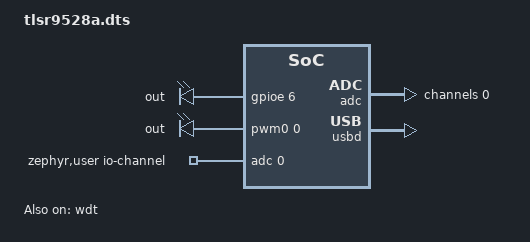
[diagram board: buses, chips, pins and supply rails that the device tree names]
/*
 * Copyright (c) 2023-2024 Telink Semiconductor
 *
 * SPDX-License-Identifier: Apache-2.0
 */

/dts-v1/;

#include "tlsr9528a-common.dtsi"

/ {
	led_pool {
		compatible = "gpio-leds";

		out {
			gpios = <&gpioe 6 GPIO_ACTIVE_HIGH>;
		};
	};

	pwm_pool {
		compatible = "pwm-leds";
		out {
			pwms =  <&pwm0 0 PWM_MSEC(1) PWM_POLARITY_NORMAL>,
					<&pwm0 1 PWM_MSEC(1) PWM_POLARITY_NORMAL>,
					<&pwm0 2 PWM_MSEC(1) PWM_POLARITY_NORMAL>,
					<&pwm0 3 PWM_MSEC(1) PWM_POLARITY_NORMAL>,
					<&pwm0 4 PWM_MSEC(1) PWM_POLARITY_NORMAL>,
					<&pwm0 5 PWM_MSEC(1) PWM_POLARITY_NORMAL>;
		};
	};

	zephyr,user {
		/* adjust channel number according to pinmux in board.dts for adc demo. */
		io-channels = <&adc 0>;
	};
};

&pwm0 {
	/* On board RGB LEDs */
	pinctrl-ch0 = <&pwm_ch0_pe7_default>;
	pinctrl-ch1 = <&pwm_ch1_pd0_default>;
	pinctrl-ch2 = <&pwm_ch2_pd3_default>;
	pinctrl-ch3 = <&pwm_ch3_pc3_default>;
	pinctrl-ch4 = <&pwm_ch4_pc2_default>;
	pinctrl-ch5 = <&pwm_ch5_pa0_default>;
};

&pinctrl {
	pwm_ch0_pe7_default: pwm_ch0_pe7_default {
		pinmux = <B9x_PINMUX_SET(B9x_PORT_E, B9x_PIN_7, B92_FUNC_PWM0)>;
	};
	pwm_ch1_pd0_default: pwm_ch1_pd0_default {
		pinmux = <B9x_PINMUX_SET(B9x_PORT_D, B9x_PIN_0, B92_FUNC_PWM1)>;
	};
	pwm_ch2_pd3_default: pwm_ch2_pd3_default {
		pinmux = <B9x_PINMUX_SET(B9x_PORT_D, B9x_PIN_3, B92_FUNC_PWM1)>;
	};
	pwm_ch3_pc3_default: pwm_ch3_pc3_default {
		pinmux = <B9x_PINMUX_SET(B9x_PORT_C, B9x_PIN_3, B92_FUNC_PWM2)>;
	};
	pwm_ch4_pc2_default: pwm_ch4_pc2_default {
		pinmux = <B9x_PINMUX_SET(B9x_PORT_C, B9x_PIN_2, B92_FUNC_PWM2)>;
	};
	pwm_ch5_pa0_default: pwm_ch5_pa0_default {
		pinmux = <B9x_PINMUX_SET(B9x_PORT_A, B9x_PIN_0, B92_FUNC_PWM2)>;
	};
};

&adc {
	/* the channel setting for adc demo. */

	#address-cells = <1>;
	#size-cells = <0>;

	channel@0 {
		reg = <0>;
		zephyr,gain = "ADC_GAIN_1_4";
		zephyr,reference = "ADC_REF_INTERNAL";
		zephyr,acquisition-time = <ADC_ACQ_TIME_DEFAULT>;
		zephyr,resolution = <12>;
		zephyr,input-positive = <DT_ADC_VBAT>;
	};
};

zephyr_udc0: &usbd {
	status = "okay";
};

&wdt {
	status = "okay";
};
